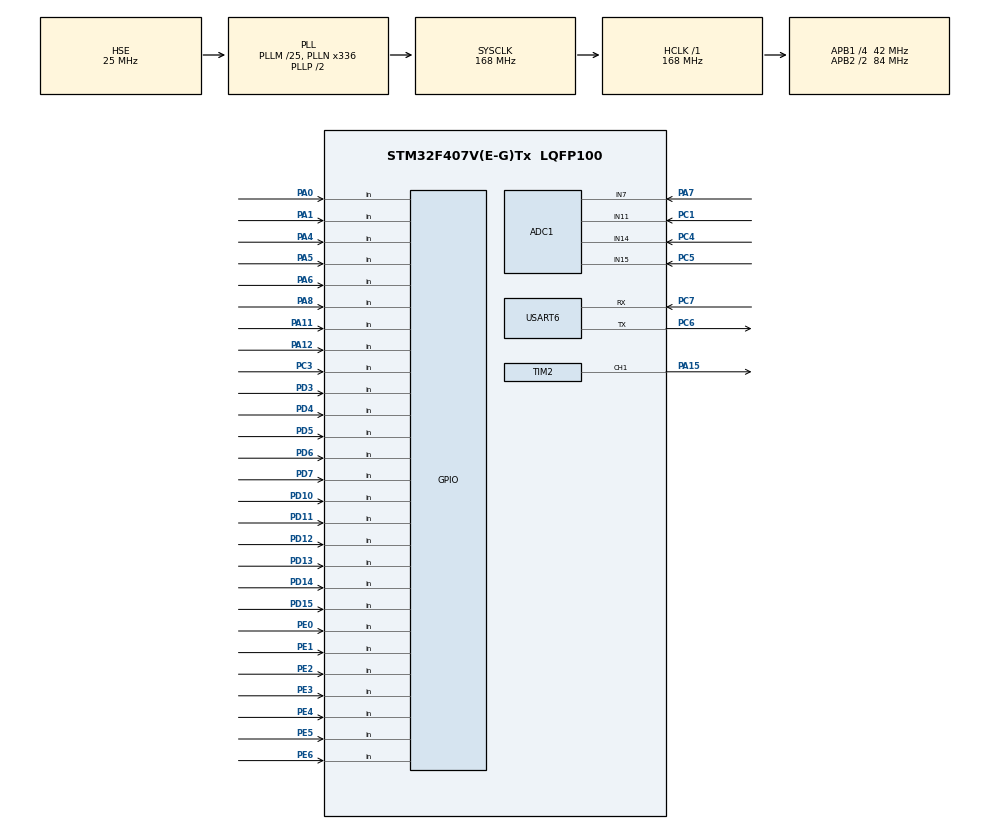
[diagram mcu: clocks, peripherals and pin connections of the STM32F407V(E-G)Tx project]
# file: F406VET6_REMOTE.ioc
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ADC1.Channel-0\#ChannelRegularConversion=ADC_CHANNEL_14
ADC1.Channel-1\#ChannelRegularConversion=ADC_CHANNEL_15
ADC1.Channel-2\#ChannelRegularConversion=ADC_CHANNEL_7
ADC1.Channel-3\#ChannelRegularConversion=ADC_CHANNEL_11
ADC1.ClockPrescaler=ADC_CLOCK_SYNC_PCLK_DIV4
ADC1.ContinuousConvMode=ENABLE
ADC1.DMAContinuousRequests=ENABLE
ADC1.NbrOfConversion=4
ADC1.NbrOfConversionFlag=1
ADC1.Rank-1\#ChannelRegularConversion=2
ADC1.Rank-2\#ChannelRegularConversion=3
ADC1.Rank-3\#ChannelRegularConversion=4
ADC1.SamplingTime-0\#ChannelRegularConversion=ADC_SAMPLETIME_144CYCLES
ADC1.SamplingTime-1\#ChannelRegularConversion=ADC_SAMPLETIME_144CYCLES
ADC1.SamplingTime-2\#ChannelRegularConversion=ADC_SAMPLETIME_144CYCLES
ADC1.SamplingTime-3\#ChannelRegularConversion=ADC_SAMPLETIME_144CYCLES
ADC1.ScanConvMode=ENABLE
ADC1.master=1
Dma.ADC1.0.Direction=DMA_PERIPH_TO_MEMORY
Dma.ADC1.0.FIFOMode=DMA_FIFOMODE_DISABLE
Dma.ADC1.0.Instance=DMA2_Stream0
Dma.ADC1.0.MemDataAlignment=DMA_MDATAALIGN_HALFWORD
Dma.ADC1.0.MemInc=DMA_MINC_ENABLE
Dma.ADC1.0.Mode=DMA_CIRCULAR
Dma.ADC1.0.PeriphDataAlignment=DMA_PDATAALIGN_HALFWORD
Dma.ADC1.0.PeriphInc=DMA_PINC_DISABLE
Dma.ADC1.0.Priority=DMA_PRIORITY_LOW
Dma.Request0=ADC1
Mcu.Family=STM32F4
Mcu.Name=STM32F407V(E-G)Tx
Mcu.Package=LQFP100
NVIC.DMA2_Stream0_IRQn=true\:0\:0\:false\:false\:true\:false\:true\:true
NVIC.PriorityGroup=NVIC_PRIORITYGROUP_4
NVIC.USART6_IRQn=true\:0\:0\:false\:false\:true\:true\:true\:true
PA0-WKUP.GPIO_PuPd=GPIO_PULLUP
PA0-WKUP.Signal=GPIO_Input
PA1.GPIO_PuPd=GPIO_PULLUP
PA1.Signal=GPIO_Input
PA11.GPIO_PuPd=GPIO_PULLUP
PA11.Signal=GPIO_Input
PA12.GPIO_PuPd=GPIO_PULLUP
PA12.Signal=GPIO_Input
PA13.Mode=Serial_Wire
PA13.Signal=SYS_JTMS-SWDIO
PA14.Mode=Serial_Wire
PA14.Signal=SYS_JTCK-SWCLK
PA15.Signal=S_TIM2_CH1_ETR
PA4.GPIO_PuPd=GPIO_PULLUP
PA4.Signal=GPIO_Input
PA5.GPIO_PuPd=GPIO_PULLUP
PA5.Signal=GPIO_Input
PA6.GPIO_PuPd=GPIO_PULLUP
PA6.Signal=GPIO_Input
PA7.Signal=ADCx_IN7
PA8.GPIO_PuPd=GPIO_PULLUP
PA8.Signal=GPIO_Input
PC1.Signal=ADCx_IN11
PC3.GPIO_PuPd=GPIO_PULLUP
PC3.Signal=GPIO_Input
PC4.Signal=ADCx_IN14
PC5.Signal=ADCx_IN15
PC6.Mode=Asynchronous
PC6.Signal=USART6_TX
PC7.Mode=Asynchronous
PC7.Signal=USART6_RX
PD10.GPIO_PuPd=GPIO_PULLUP
PD10.Signal=GPIO_Input
PD11.GPIO_PuPd=GPIO_PULLUP
PD11.Signal=GPIO_Input
PD12.GPIO_PuPd=GPIO_PULLUP
PD12.Signal=GPIO_Input
PD13.GPIO_PuPd=GPIO_PULLUP
PD13.Signal=GPIO_Input
PD14.GPIO_PuPd=GPIO_PULLUP
PD14.Signal=GPIO_Input
PD15.GPIO_PuPd=GPIO_PULLUP
PD15.Signal=GPIO_Input
PD3.GPIO_PuPd=GPIO_PULLUP
PD3.Signal=GPIO_Input
PD4.GPIO_PuPd=GPIO_PULLUP
PD4.Signal=GPIO_Input
PD5.GPIO_PuPd=GPIO_PULLUP
PD5.Signal=GPIO_Input
PD6.GPIO_PuPd=GPIO_PULLUP
PD6.Signal=GPIO_Input
PD7.GPIO_PuPd=GPIO_PULLUP
PD7.Signal=GPIO_Input
PE0.GPIO_PuPd=GPIO_PULLUP
PE0.Signal=GPIO_Input
PE1.GPIO_PuPd=GPIO_PULLUP
PE1.Signal=GPIO_Input
PE2.GPIO_PuPd=GPIO_PULLUP
PE2.Signal=GPIO_Input
PE3.GPIO_PuPd=GPIO_PULLUP
PE3.Signal=GPIO_Input
PE4.GPIO_PuPd=GPIO_PULLUP
PE4.Signal=GPIO_Input
PE5.GPIO_PuPd=GPIO_PULLUP
PE5.Signal=GPIO_Input
PE6.GPIO_PuPd=GPIO_PULLUP
PE6.Signal=GPIO_Input
PH0-OSC_IN.Mode=HSE-External-Oscillator
PH0-OSC_IN.Signal=RCC_OSC_IN
PH1-OSC_OUT.Mode=HSE-External-Oscillator
PH1-OSC_OUT.Signal=RCC_OSC_OUT
ProjectManager.HeapSize=0x200
ProjectManager.StackSize=0x400
ProjectManager.TargetToolchain=MDK-ARM V5.32
RCC.48MHZClocksFreq_Value=84000000
RCC.AHBFreq_Value=168000000
RCC.APB1CLKDivider=RCC_HCLK_DIV4
RCC.APB1Freq_Value=42000000
RCC.APB1TimFreq_Value=84000000
RCC.APB2CLKDivider=RCC_HCLK_DIV2
RCC.APB2Freq_Value=84000000
RCC.APB2TimFreq_Value=168000000
RCC.CortexFreq_Value=168000000
RCC.HCLKFreq_Value=168000000
RCC.HSE_VALUE=25000000
RCC.HSI_VALUE=16000000
RCC.LSE_VALUE=32768
RCC.PLLM=25
RCC.PLLN=336
RCC.PLLSourceVirtual=RCC_PLLSOURCE_HSE
RCC.SYSCLKFreq_VALUE=168000000
RCC.SYSCLKSource=RCC_SYSCLKSOURCE_PLLCLK
RCC.VCOOutputFreq_Value=336000000
SH.ADCx_IN11.0=ADC1_IN11,IN11
SH.ADCx_IN14.0=ADC1_IN14,IN14
SH.ADCx_IN15.0=ADC1_IN15,IN15
SH.ADCx_IN7.0=ADC1_IN7,IN7
SH.S_TIM2_CH1_ETR.0=TIM2_CH1,PWM Generation1 CH1
TIM2.Channel-PWM\ Generation1\ CH1=TIM_CHANNEL_1
TIM2.Period=999
TIM2.Prescaler=83
TIM2.Pulse-PWM\ Generation1\ CH1=500
USART6.VirtualMode=VM_ASYNC
board=custom

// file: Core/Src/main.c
/* USER CODE BEGIN Header */
/**
  ******************************************************************************
  * @file           : main.c
  * @brief          : Main program body
  ******************************************************************************
  * @attention
  *
  * Copyright (c) 2026 STMicroelectronics.
  * All rights reserved.
  *
  * This software is licensed under terms that can be found in the LICENSE file
  * in the root directory of this software component.
  * If no LICENSE file comes with this software, it is provided AS-IS.
  *
  ******************************************************************************
  */
/* USER CODE END Header */
#include "main.h"
#include "adc.h"
#include "dma.h"
#include "tim.h"
#include "usart.h"
#include "gpio.h"

/* USER CODE BEGIN Includes */
#include "my_main.h"
/* USER CODE END Includes */

void SystemClock_Config(void);

int main(void)
{

  /* MCU Configuration--------------------------------------------------------*/

  /* Reset of all peripherals, Initializes the Flash interface and the Systick. */
  HAL_Init();

  /* Configure the system clock */
  SystemClock_Config();

  /* Initialize all configured peripherals */
  MX_GPIO_Init();
  MX_DMA_Init();
  MX_ADC1_Init();
  MX_USART6_UART_Init();
  MX_TIM2_Init();
  /* USER CODE BEGIN 2 */
  My_Init();
  /* USER CODE END 2 */

  /* Infinite loop */
  /* USER CODE BEGIN WHILE */
  while (1)
  {
    My_Loop();
    /* USER CODE END WHILE */

  }
}

void SystemClock_Config(void)
{
  RCC_OscInitTypeDef RCC_OscInitStruct = {0};
  RCC_ClkInitTypeDef RCC_ClkInitStruct = {0};

  /** Configure the main internal regulator output voltage
  */
  __HAL_RCC_PWR_CLK_ENABLE();
  __HAL_PWR_VOLTAGESCALING_CONFIG(PWR_REGULATOR_VOLTAGE_SCALE1);

  /** Initializes the RCC Oscillators according to the specified parameters
  * in the RCC_OscInitTypeDef structure.
  */
  RCC_OscInitStruct.OscillatorType = RCC_OSCILLATORTYPE_HSE;
  RCC_OscInitStruct.HSEState = RCC_HSE_ON;
  RCC_OscInitStruct.PLL.PLLState = RCC_PLL_ON;
  RCC_OscInitStruct.PLL.PLLSource = RCC_PLLSOURCE_HSE;
  RCC_OscInitStruct.PLL.PLLM = 25;
  RCC_OscInitStruct.PLL.PLLN = 336;
  RCC_OscInitStruct.PLL.PLLP = RCC_PLLP_DIV2;
  RCC_OscInitStruct.PLL.PLLQ = 4;
  if (HAL_RCC_OscConfig(&RCC_OscInitStruct) != HAL_OK)
  {
    Error_Handler();
  }

  /** Initializes the CPU, AHB and APB buses clocks
  */
  RCC_ClkInitStruct.ClockType = RCC_CLOCKTYPE_HCLK|RCC_CLOCKTYPE_SYSCLK
                              |RCC_CLOCKTYPE_PCLK1|RCC_CLOCKTYPE_PCLK2;
  RCC_ClkInitStruct.SYSCLKSource = RCC_SYSCLKSOURCE_PLLCLK;
  RCC_ClkInitStruct.AHBCLKDivider = RCC_SYSCLK_DIV1;
  RCC_ClkInitStruct.APB1CLKDivider = RCC_HCLK_DIV4;
  RCC_ClkInitStruct.APB2CLKDivider = RCC_HCLK_DIV2;

  if (HAL_RCC_ClockConfig(&RCC_ClkInitStruct, FLASH_LATENCY_5) != HAL_OK)
  {
    Error_Handler();
  }
}

void Error_Handler(void)
{
  __disable_irq();
  while (1)
  {
  }
}
